# PIC32CM2532LE00048 register map
Vendor: Microchip Technology; Series: PIC32CMLE00; File version: 0
CPU: CM23 r0p0, little endian, MPU, no FPU, 2 interrupt priority bits, 71 interrupts
Registers are 32-bit, read-write, reset 0x0 unless marked. A register's access mark holds for its fields unless they carry their own. Offsets are from the block's base; [hi:lo] are bit positions; {n}, {i} and the like mark numbered series.

## PAC — Peripheral Access Controller
Base 0x40000000
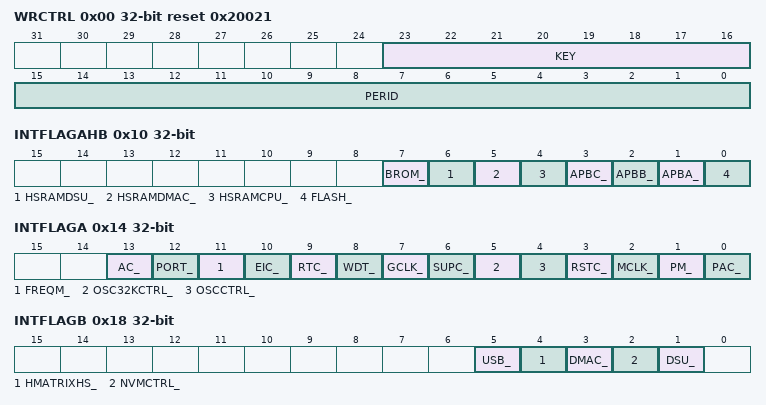
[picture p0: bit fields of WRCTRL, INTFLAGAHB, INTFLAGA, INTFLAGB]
0x00 WRCTRL reset 0x20021 — Write control
  [23:16] KEY — Peripheral access control key
    0=OFF (No action); 1=CLR (Clear protection); 2=SET (Set protection); 3=SETLCK (Set and lock protection)
  [15:0] PERID — Peripheral identifier
0x04 EVCTRL 8-bit — Event control
  [0] ERREO — Peripheral acess error event output
0x08 INTENCLR 8-bit write-1-clears — Interrupt enable clear
  [0] ERR — Peripheral access error interrupt disable
0x09 INTENSET 8-bit write-1-sets — Interrupt enable set
  [0] ERR — Peripheral access error interrupt enable
0x10 INTFLAGAHB write-1-clears — Bridge interrupt flag status
  [7] BROM_, [6] HSRAMDSU_, [5] HSRAMDMAC_, [4] HSRAMCPU_, [3] APBC_, [2] APBB_, [1] APBA_, [0] FLASH_
0x14 INTFLAGA write-1-clears — Peripheral interrupt flag status - Bridge A
  [13] AC_, [12] PORT_, [11] FREQM_, [10] EIC_, [9] RTC_, [8] WDT_, [7] GCLK_, [6] SUPC_, [5] OSC32KCTRL_, [4] OSCCTRL_, [3] RSTC_, [2] MCLK_, [1] PM_, [0] PAC_
0x18 INTFLAGB write-1-clears — Peripheral interrupt flag status - Bridge B
  [5] USB_, [4] HMATRIXHS_, [3] DMAC_, [2] NVMCTRL_, [1] DSU_
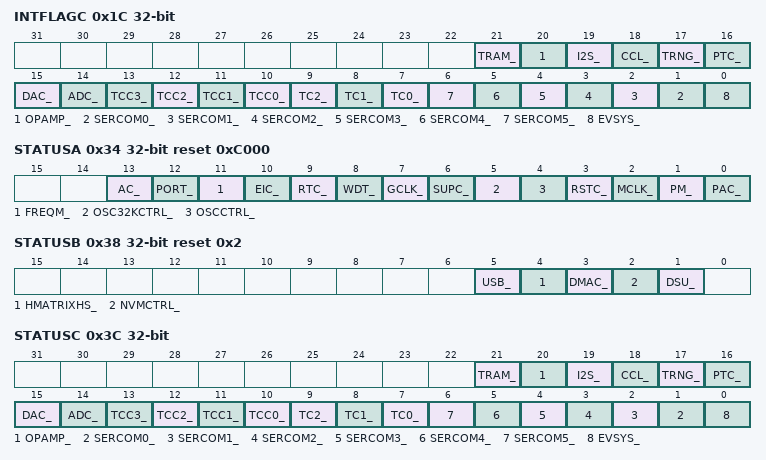
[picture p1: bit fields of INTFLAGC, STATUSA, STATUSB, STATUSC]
0x1C INTFLAGC write-1-clears — Peripheral interrupt flag status - Bridge C
  [21] TRAM_, [20] OPAMP_, [19] I2S_, [18] CCL_, [17] TRNG_, [16] PTC_, [15] DAC_, [14] ADC_, [n+10] TCC{n}_ (n=0..3), [9] TC2_, [8] TC1_, [7] TC0_, [n+1] SERCOM{n}_ (n=0..5), [0] EVSYS_
0x34 STATUSA ro reset 0xC000 — Peripheral write protection status - Bridge A
  [13] AC_ — AC APB Protect Enable
  [12] PORT_ — PORT APB Protect Enable
  [11] FREQM_ — FREQM APB Protect Enable
  [10] EIC_ — EIC APB Protect Enable
  [9] RTC_ — RTC APB Protect Enable
  [8] WDT_ — WDT APB Protect Enable
  [7] GCLK_ — GCLK APB Protect Enable
  [6] SUPC_ — SUPC APB Protect Enable
  [5] OSC32KCTRL_ — OSC32KCTRL APB Protect Enable
  [4] OSCCTRL_ — OSCCTRL APB Protect Enable
  [3] RSTC_ — RSTC APB Protect Enable
  [2] MCLK_ — MCLK APB Protect Enable
  [1] PM_ — PM APB Protect Enable
  [0] PAC_ — PAC APB Protect Enable
0x38 STATUSB ro reset 0x2 — Peripheral write protection status - Bridge B
  [5] USB_ — USB APB Protect Enable
  [4] HMATRIXHS_ — HMATRIXHS APB Protect Enable
  [3] DMAC_ — DMAC APB Protect Enable
  [2] NVMCTRL_ — NVMCTRL APB Protect Enable
  [1] DSU_ — DSU APB Protect Enable
0x3C STATUSC ro — Peripheral write protection status - Bridge C
  [21] TRAM_ — TRAM APB Protect Enable
  [20] OPAMP_ — OPAMP APB Protect Enable
  [19] I2S_ — I2S APB Protect Enable
  [18] CCL_ — CCL APB Protect Enable
  [17] TRNG_ — TRNG APB Protect Enable
  [16] PTC_ — PTC APB Protect Enable
  [15] DAC_ — DAC APB Protect Enable
  [14] ADC_ — ADC APB Protect Enable
  [n+10] TCC{n}_ (n=0..3) — TCC{n} APB Protect Enable
  [9] TC2_ — TC2 APB Protect Enable
  [8] TC1_ — TC1 APB Protect Enable
  [7] TC0_ — TC0 APB Protect Enable
  [n+1] SERCOM{n}_ (n=0..5) — SERCOM{n} APB Protect Enable
  [0] EVSYS_ — EVSYS APB Protect Enable

## PM — Power Manager
Base 0x40000400
0x01 SLEEPCFG 8-bit reset 0x2 — Sleep Configuration
  [2:0] SLEEPMODE
    2=IDLE (CPU, AHBx, and APBx clocks are OFF); 4=STANDBY (ALL clocks are OFF, unless requested by sleepwalking peripheral); 6=OFF (All power domains are powered OFF)
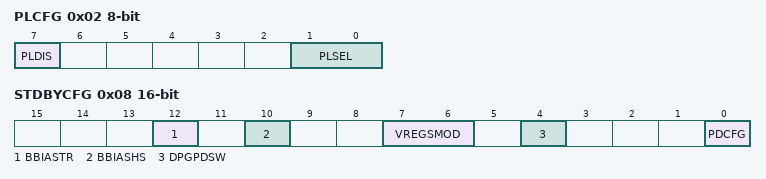
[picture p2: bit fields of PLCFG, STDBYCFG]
0x02 PLCFG 8-bit — Performance Level Configuration
  [7] PLDIS — Performance Level Disable
  [1:0] PLSEL — Performance Level Select
    0=PL0 (Performance Level 0); 2=PL2 (Performance Level 2)
0x03 PWCFG 8-bit — Power Configuration
  [1:0] RAMPSWC — RAM Power Switch Configuration
    0=SIZE0 (SRAM Retention: 64KB (512KB Flash), 32KB (256KB Flash), 16KB (128KB Flash)); 1=SIZE1 (SRAM Retention: 48KB (512KB Flash), 32KB (256KB Flash), 12KB (128KB Flash)); 2=SIZE2 (SRAM Retention: 32KB (512KB Flash), 32KB (256KB Flash), 8KB (128KB Flash)); 3=SIZE3 (SRAM Retention: 16KB (512KB Flash), 16KB (256KB Flash), 4KB (128KB Flash))
0x04 INTENCLR 8-bit write-1-clears — Interrupt Enable Clear
  [0] PLRDY — Performance Level Interrupt Enable
0x05 INTENSET 8-bit write-1-sets — Interrupt Enable Set
  [0] PLRDY — Performance Level Ready interrupt Enable
0x06 INTFLAG 8-bit write-1-clears — Interrupt Flag Status and Clear
  [0] PLRDY — Performance Level Ready
0x08 STDBYCFG 16-bit — Standby Configuration
  [12] BBIASTR — Back Bias for Trust RAM
  [10] BBIASHS — Back Bias for SRAM
  [7:6] VREGSMOD — Voltage Regulator Standby mode
    0=AUTO (Automatic mode); 1=PERFORMANCE (Performance oriented); 2=LP (Low Power oriented)
  [4] DPGPDSW — Dynamic Power Gating for PDSW
    0=DISABLED (Dynamic Power Gating disabled); 1=ENABLED (Dynamic Power Gating enabled)
  [0] PDCFG — Power Domain Configuration
    0=DEFAULT (PDSW power domain switching is handled by hardware.); 1=PDSW (PDSW is forced ACTIVE.)

## Notices in the file
Copyright (c) 2026 Microchip Technology Inc.
SPDX-License-Identifier: Apache-2.0
Licensed under the Apache License, Version 2.0 (the "License");
you may not use this file except in compliance with the License.
You may obtain a copy of the License at
http://www.apache.org/licenses/LICENSE-2.0
Unless required by applicable law or agreed to in writing, software
distributed under the License is distributed on an "AS IS" BASIS,
WITHOUT WARRANTIES OR CONDITIONS OF ANY KIND, either express or implied.
See the License for the specific language governing permissions and
limitations under the License.
